# BL602 register map
Vendor: bouffalolab; Series: WiFi BT
Registers are 32-bit, read-write, reset 0x0 unless marked. A register's access mark holds for its fields unless they carry their own. Offsets are from the block's base; [hi:lo] are bit positions.

## CLIC — Hart 0 Core-local interrupt controller
Base 0x02800000
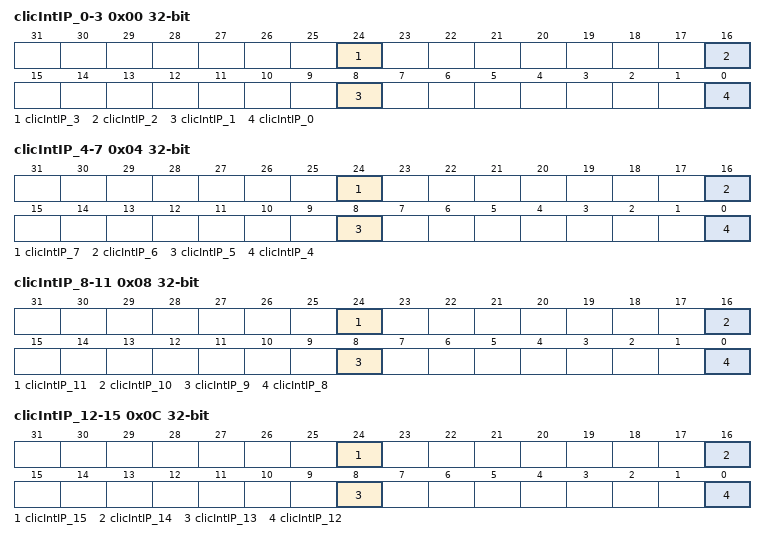
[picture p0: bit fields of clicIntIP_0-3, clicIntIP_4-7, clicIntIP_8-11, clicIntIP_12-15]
0x00 clicIntIP_0-3
  [24] clicIntIP_3 — Machine Software Interrupt Pending (MSIP)
  [16] clicIntIP_2 ro
  [8] clicIntIP_1 ro
  [0] clicIntIP_0 ro
0x04 clicIntIP_4-7
  [24] clicIntIP_7 ro — Machine Timer Interrupt Pending (MTIP)
  [16] clicIntIP_6 ro
  [8] clicIntIP_5 ro
  [0] clicIntIP_4 ro
0x08 clicIntIP_8-11
  [24] clicIntIP_11 ro — Machine External Interrupt Pending (MEIP)
  [16] clicIntIP_10 ro
  [8] clicIntIP_9 ro
  [0] clicIntIP_8 ro
0x0C clicIntIP_12-15
  [24] clicIntIP_15 ro
  [16] clicIntIP_14 ro
  [8] clicIntIP_13 ro
  [0] clicIntIP_12 — CLIC Software Interrupt Pending (CSIP)
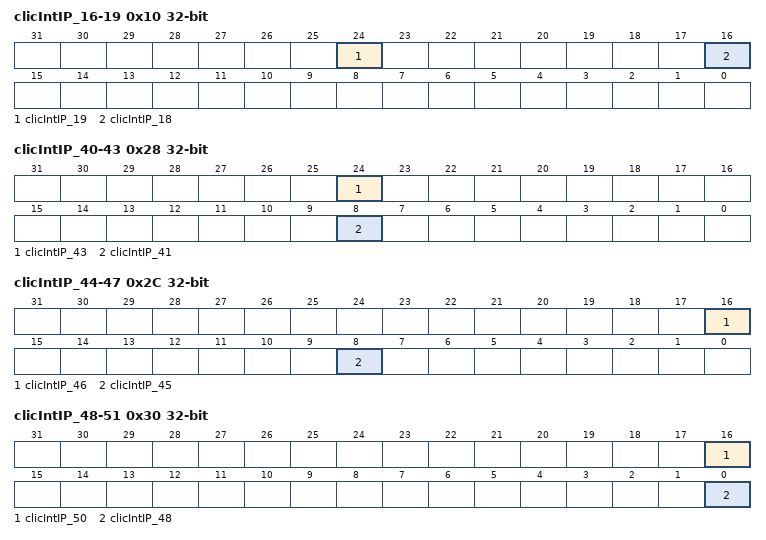
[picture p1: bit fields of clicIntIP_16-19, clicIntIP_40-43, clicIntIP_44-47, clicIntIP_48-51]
0x10 clicIntIP_16-19
  [24] clicIntIP_19 ro — L1C BMX Timeout Interrupt Pending
  [16] clicIntIP_18 ro — L1C BMX Error Interrupt Pending
0x18 clicIntIP_24-27
  [0] clicIntIP_24 ro — DMA BMX Error Interrupt Pending
0x20 clicIntIP_32-35
  [24] clicIntIP_35 ro — IR TX Interrupt Pending
0x24 clicIntIP_36-39
  [0] clicIntIP_36 ro — IR RX Interrupt Pending
0x28 clicIntIP_40-43
  [24] clicIntIP_43 ro — SPI Interrupt Pending
  [8] clicIntIP_41 ro — GPADC_DMA Interrupt Pending
0x2C clicIntIP_44-47
  [16] clicIntIP_46 ro — UART1 Interrupt Pending
  [8] clicIntIP_45 ro — UART0 Interrupt Pending
0x30 clicIntIP_48-51
  [16] clicIntIP_50 ro — PWM Interrupt Pending
  [0] clicIntIP_48 ro — I2C Interrupt Pending
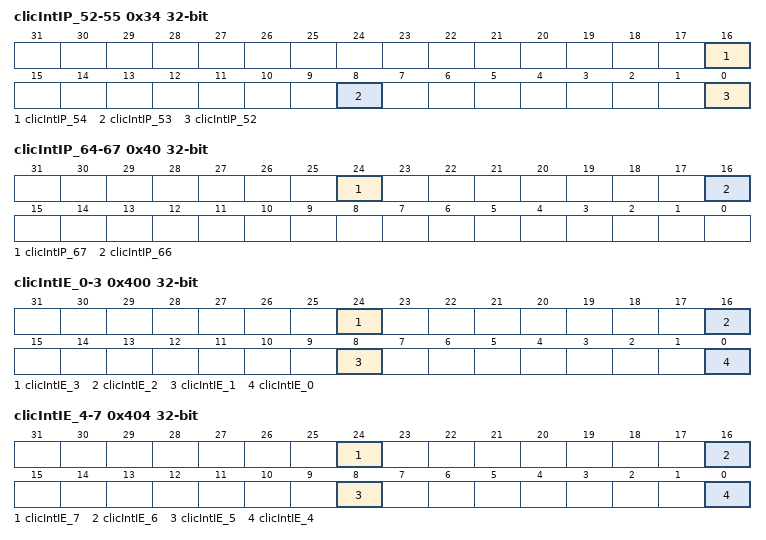
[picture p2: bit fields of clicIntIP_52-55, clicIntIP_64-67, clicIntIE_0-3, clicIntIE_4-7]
0x34 clicIntIP_52-55
  [16] clicIntIP_54 ro — Watch Dog Interrupt Pending
  [8] clicIntIP_53 ro — Timer Channel 1 Interrupt Pending
  [0] clicIntIP_52 ro — Timer Channel 0 Interrupt Pending
0x3C clicIntIP_60-63
  [0] clicIntIP_60 ro — GPIO Interrupt Pending
0x40 clicIntIP_64-67
  [24] clicIntIP_67 ro — Hibernate out 0 Interrupt Pending
  [16] clicIntIP_66 ro — PDS Wakeup Interrupt Pending
0x44 clicIntIP_68-71
  [0] clicIntIP_68 ro — Hibernate out 0 Interrupt Pending
0x400 clicIntIE_0-3
  [24] clicIntIE_3 — Machine Software Interrupt Enable (msie)
  [16] clicIntIE_2
  [8] clicIntIE_1
  [0] clicIntIE_0
0x404 clicIntIE_4-7
  [24] clicIntIE_7 — Machine Timer Interrupt Enable (mtie)
  [16] clicIntIE_6
  [8] clicIntIE_5
  [0] clicIntIE_4
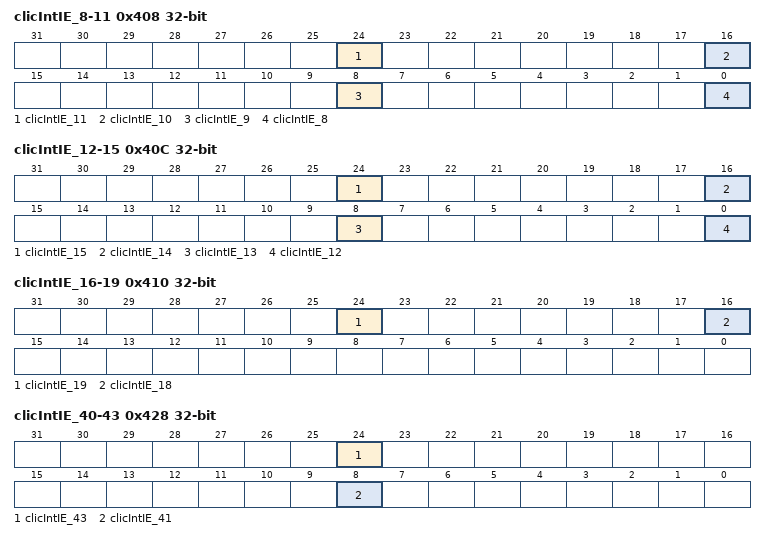
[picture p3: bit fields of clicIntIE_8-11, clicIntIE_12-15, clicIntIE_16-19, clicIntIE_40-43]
0x408 clicIntIE_8-11
  [24] clicIntIE_11 — Machine External Interrupt Enable (meie)
  [16] clicIntIE_10
  [8] clicIntIE_9
  [0] clicIntIE_8
0x40C clicIntIE_12-15
  [24] clicIntIE_15
  [16] clicIntIE_14
  [8] clicIntIE_13
  [0] clicIntIE_12 — CLIC Software Interrupt Enable
0x410 clicIntIE_16-19
  [24] clicIntIE_19 — L1C BMX Timeout Interrupt Enable
  [16] clicIntIE_18 — L1C BMX Error Interrupt Enable
0x418 clicIntIE_24-27
  [0] clicIntIE_24 — DMA BMX Error Interrupt Enable
0x420 clicIntIE_32-35
  [24] clicIntIE_35 — IR TX Interrupt Enable
0x424 clicIntIE_36-39
  [0] clicIntIE_36 — IR RX Interrupt Enable
0x428 clicIntIE_40-43
  [24] clicIntIE_43 — SPI Interrupt Enable
  [8] clicIntIE_41 — GPADC_DMA Interrupt Enable
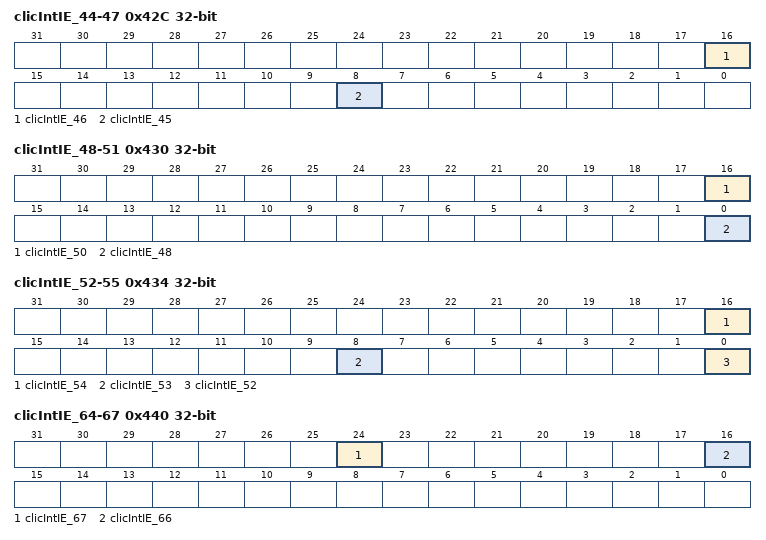
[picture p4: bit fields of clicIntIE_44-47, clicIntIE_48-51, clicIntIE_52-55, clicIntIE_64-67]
0x42C clicIntIE_44-47
  [16] clicIntIE_46 — UART1 Interrupt Enable
  [8] clicIntIE_45 — UART0 Interrupt Enable
0x430 clicIntIE_48-51
  [16] clicIntIE_50 — PWM Interrupt Enable
  [0] clicIntIE_48 — I2C Interrupt Enable
0x434 clicIntIE_52-55
  [16] clicIntIE_54 — Watch Dog Interrupt Enable
  [8] clicIntIE_53 — Timer Channel 1 Interrupt Enable
  [0] clicIntIE_52 — Timer Channel 0 Interrupt Enable
0x43C clicIntIE_60-63
  [0] clicIntIE_60 — GPIO Interrupt Enable
0x440 clicIntIE_64-67
  [24] clicIntIE_67 — Hibernate out 0 Interrupt Enable
  [16] clicIntIE_66 — PDS Wakeup Interrupt Enable
0x444 clicIntIE_68-71
  [0] clicIntIE_68 — Hibernate out 0 Interrupt Enable
0x800 clicIntCfg_0-3 reset 0xF000000
  [31:28] clicIntCfg_3 — Machine Software Interrupt Configuration
0x804 clicIntCfg_4-7 reset 0xF000000
  [31:28] clicIntCfg_7 — Machine Timer Interrupt Configuration
0x808 clicIntCfg_8-11 reset 0xF000000
  [31:28] clicIntCfg_11 — Machine External Interrupt Configuration
0x80C clicIntCfg_12-15 reset 0xF
  [7:4] clicIntCfg_12 — CLIC Software Interrupt Configuration
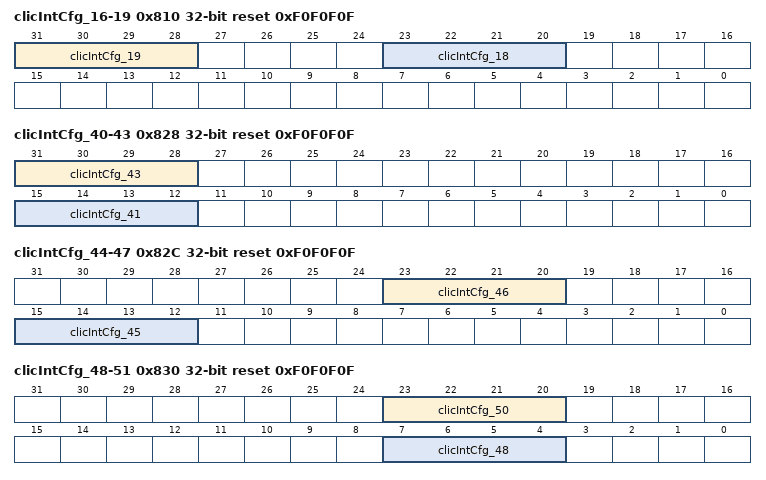
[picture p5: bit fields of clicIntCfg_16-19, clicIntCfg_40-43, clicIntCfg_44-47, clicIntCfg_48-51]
0x810 clicIntCfg_16-19 reset 0xF0F0F0F
  [31:28] clicIntCfg_19 — L1C BMX Timeout Interrupt Configuration
  [23:20] clicIntCfg_18 — L1C BMX Error Interrupt Configuration
0x818 clicIntCfg_24-27 reset 0xF0F0F0F
  [7:4] clicIntCfg_24 — DMA BMX Error Interrupt Configuration
0x820 clicIntCfg_32-35 reset 0xF0F0F0F
  [31:28] clicIntCfg_35 — IR TX Interrupt Configuration
0x824 clicIntCfg_36-39 reset 0xF0F0F0F
  [7:4] clicIntCfg_36 — IR RX Interrupt Configuration
0x828 clicIntCfg_40-43 reset 0xF0F0F0F
  [31:28] clicIntCfg_43 — SPI Interrupt Configuration
  [15:12] clicIntCfg_41 — GPADC_DMA Interrupt Configuration
0x82C clicIntCfg_44-47 reset 0xF0F0F0F
  [23:20] clicIntCfg_46 — UART1 Interrupt Configuration
  [15:12] clicIntCfg_45 — UART0 Interrupt Configuration
0x830 clicIntCfg_48-51 reset 0xF0F0F0F
  [23:20] clicIntCfg_50 — PWM Interrupt Configuration
  [7:4] clicIntCfg_48 — I2C Interrupt Configuration
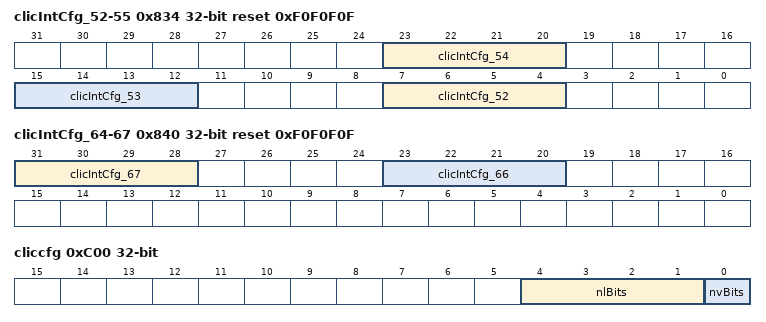
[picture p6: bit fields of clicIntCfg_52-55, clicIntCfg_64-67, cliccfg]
0x834 clicIntCfg_52-55 reset 0xF0F0F0F
  [23:20] clicIntCfg_54 — Watch Dog Interrupt Configuration
  [15:12] clicIntCfg_53 — Timer Channel 1 Interrupt Configuration
  [7:4] clicIntCfg_52 — Timer Channel 0 Interrupt Configuration
0x83C clicIntCfg_60-63 reset 0xF0F0F0F
  [7:4] clicIntCfg_60 — GPIO Interrupt Configuration
0x840 clicIntCfg_64-67 reset 0xF0F0F0F
  [31:28] clicIntCfg_67 — Hibernate out 0 Interrupt Configuration
  [23:20] clicIntCfg_66 — PDS Wakeup Interrupt Configuration
0x844 clicIntCfg_68-71 reset 0xF0F0F0F
  [7:4] clicIntCfg_68 — Hibernate out 0 Interrupt Configuration
0xC00 cliccfg
  [4:1] nlBits — number of level bits in clicIntCfg
  [0] nvBits — selective hardware vectoring enable
